# SWM181 register map
File version: 1.0
CPU: CM0 r1p0, little endian, 2 interrupt priority bits
Registers are 32-bit, read-write, no defined reset value unless marked. A register's access mark holds for its fields unless they carry their own. Offsets are from the block's base; [hi:lo] are bit positions; lines under a group give offsets from that group; {n}, {i} and the like mark numbered series; 'fields as' and 'values as' point back to an identical list.

## ADC — Registers group
Base 0x5000D000
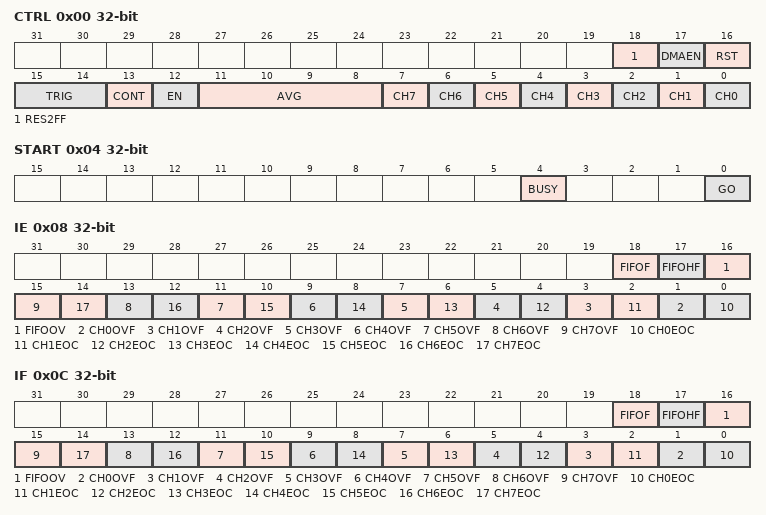
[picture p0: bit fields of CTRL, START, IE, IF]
0x00 CTRL
  [18] RES2FF, [17] DMAEN, [16] RST, [15:14] TRIG, [13] CONT, [12] EN, [11:8] AVG, [n] CH{n} (n=0..7)
0x04 START
  [4] BUSY, [0] GO
0x08 IE
  [18] FIFOF, [17] FIFOHF, [16] FIFOOV, [2n+1] CH{n}OVF (n=0..7), [2n] CH{n}EOC (n=0..7)
0x0C IF
  fields as IE
{0x10+0x10*i} CH{i} group (i=0..7) — register cluster
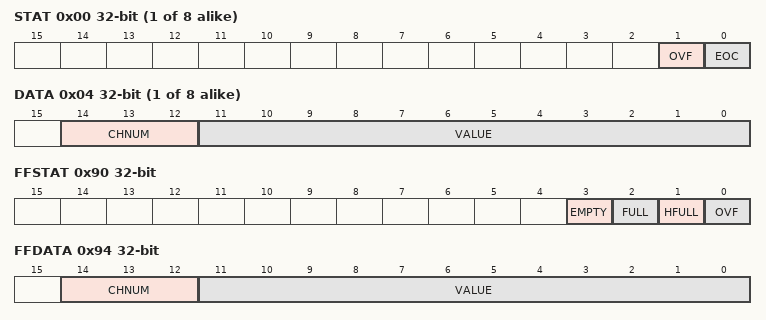
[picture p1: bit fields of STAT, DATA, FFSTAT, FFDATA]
  0x00 STAT
    [1] OVF, [0] EOC
  0x04 DATA
    [14:12] CHNUM, [11:0] VALUE
0x90 FFSTAT
  [3] EMPTY, [2] FULL, [1] HFULL, [0] OVF
0x94 FFDATA
  [14:12] CHNUM, [11:0] VALUE

## SDADC — Registers group
Base 0x50040000
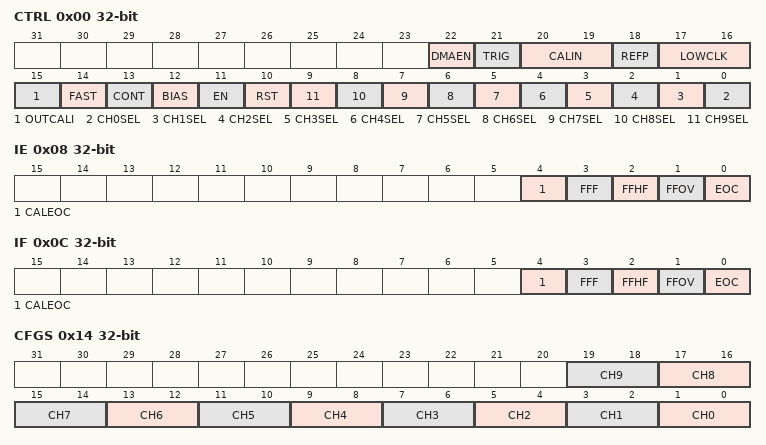
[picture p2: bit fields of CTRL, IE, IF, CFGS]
0x00 CTRL
  [22] DMAEN, [21] TRIG, [20:19] CALIN, [18] REFP, [17:16] LOWCLK, [15] OUTCALI, [14] FAST, [13] CONT, [12] BIAS, [11] EN, [10] RST, [n] CH{n}SEL (n=0..9)
0x04 START
  [0] GO
0x08 IE
  [4] CALEOC, [3] FFF, [2] FFHF, [1] FFOV, [0] EOC
0x0C IF
  [4] CALEOC, [3] FFF, [2] FFHF, [1] FFOV, [0] EOC
0x14 CFGS
  [2n+1:2n] CH{n} (n=0..9)
0x20 CFGA
0x24 CFGB
0x28 CFGC
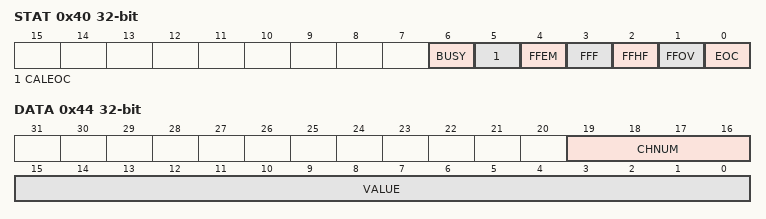
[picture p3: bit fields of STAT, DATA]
0x40 STAT
  [6] BUSY, [5] CALEOC, [4] FFEM, [3] FFF, [2] FFHF, [1] FFOV, [0] EOC
0x44 DATA
  [19:16] CHNUM, [15:0] VALUE

## PWM0 — Registers group
Base 0x5000A000
Same registers: PWM1 0x5000A020, PWM2 0x5000A040, PWM3 0x5000A060
0x00 MODE
0x04 PERA
0x08 HIGHA
0x0C DZA
0x10 PERB
0x14 HIGHB
0x18 DZB
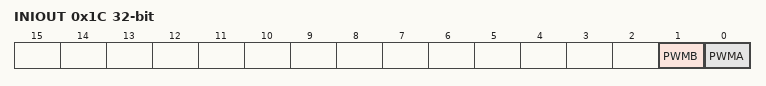
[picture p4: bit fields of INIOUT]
0x1C INIOUT
  [1] PWMB, [0] PWMA

## PWMG — Registers group
Base 0x5000A170
0x00 CLKDIV
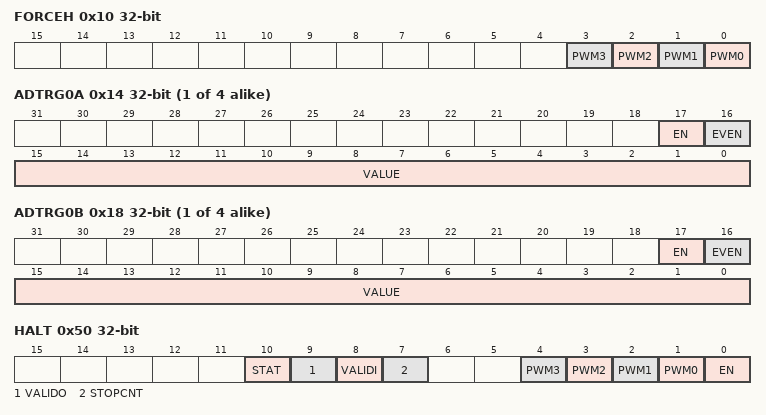
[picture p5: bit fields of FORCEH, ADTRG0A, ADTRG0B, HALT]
0x10 FORCEH
  [n] PWM{n} (n=0..3)
{0x14+8i} ADTRG{i}A (i=0..3)
  [17] EN, [16] EVEN, [15:0] VALUE
{0x18+8i} ADTRG{i}B (i=0..3)
  [17] EN, [16] EVEN, [15:0] VALUE
0x50 HALT
  [10] STAT, [9] VALIDO, [8] VALIDI, [7] STOPCNT, [n+1] PWM{n} (n=0..3), [0] EN
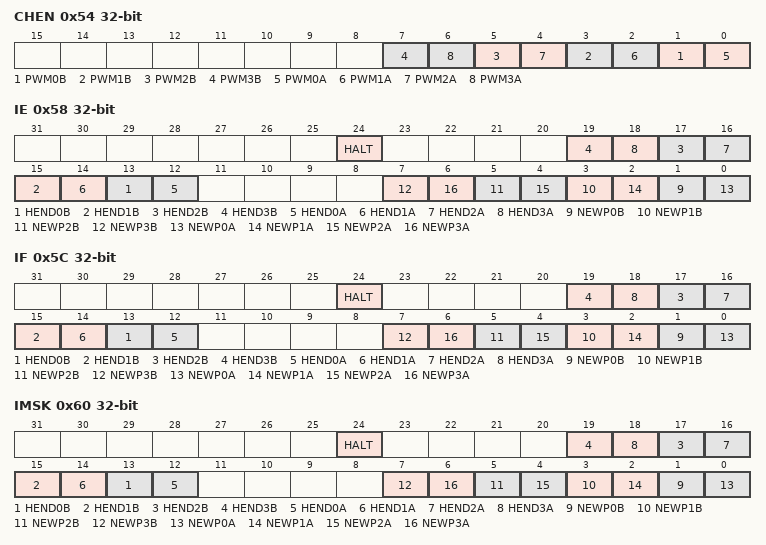
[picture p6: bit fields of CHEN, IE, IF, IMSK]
0x54 CHEN
  [2n+1] PWM{n}B (n=0..3), [2n] PWM{n}A (n=0..3)
0x58 IE
  [24] HALT, [2n+13] HEND{n}B (n=0..3), [2n+12] HEND{n}A (n=0..3), [2n+1] NEWP{n}B (n=0..3), [2n] NEWP{n}A (n=0..3)
0x5C IF
  fields as IE
0x60 IMSK
  fields as IE
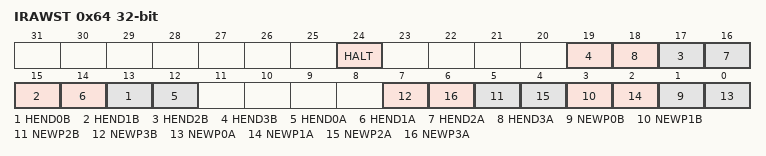
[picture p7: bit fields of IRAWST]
0x64 IRAWST
  fields as IE

## DMA — Registers group
Base 0x41000000
0x00 EN
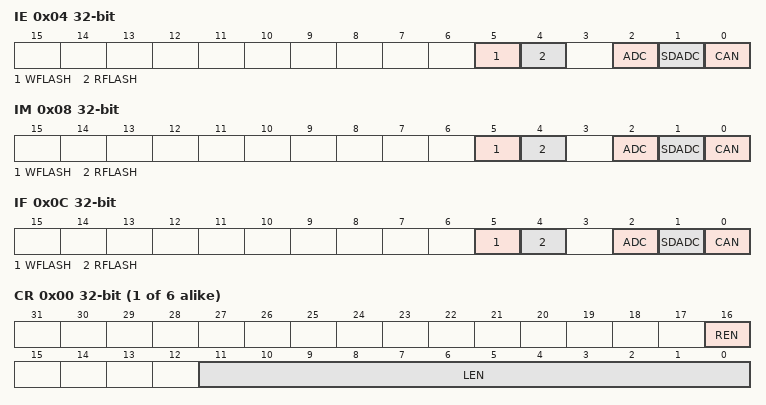
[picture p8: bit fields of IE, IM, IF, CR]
0x04 IE
  [5] WFLASH, [4] RFLASH, [2] ADC, [1] SDADC, [0] CAN
0x08 IM
  [5] WFLASH, [4] RFLASH, [2] ADC, [1] SDADC, [0] CAN
0x0C IF
  [5] WFLASH, [4] RFLASH, [2] ADC, [1] SDADC, [0] CAN
{0x10+0xC*i} CH{i} group (i=0..5) — register cluster
  0x00 CR
    [16] REN, [11:0] LEN
  0x04 SRC
  0x08 DST

## CAN — Registers group
Base 0x50020000
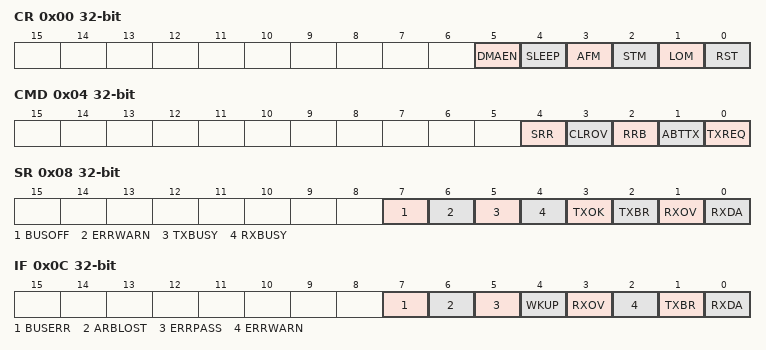
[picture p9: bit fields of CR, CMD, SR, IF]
0x00 CR
  [5] DMAEN, [4] SLEEP, [3] AFM, [2] STM, [1] LOM, [0] RST
0x04 CMD wo
  [4] SRR, [3] CLROV, [2] RRB, [1] ABTTX, [0] TXREQ
0x08 SR ro
  [7] BUSOFF, [6] ERRWARN, [5] TXBUSY, [4] RXBUSY, [3] TXOK, [2] TXBR, [1] RXOV, [0] RXDA
0x0C IF ro
  [7] BUSERR, [6] ARBLOST, [5] ERRPASS, [4] WKUP, [3] RXOV, [2] ERRWARN, [1] TXBR, [0] RXDA
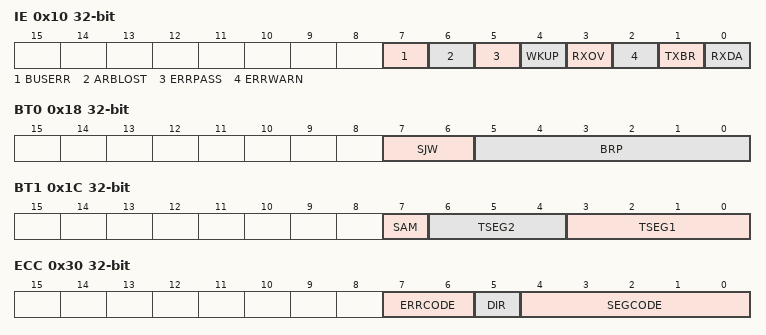
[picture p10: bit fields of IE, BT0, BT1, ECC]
0x10 IE
  fields as IF
0x18 BT0
  [7:6] SJW, [5:0] BRP
0x1C BT1
  [7] SAM, [6:4] TSEG2, [3:0] TSEG1
0x2C ALC ro
0x30 ECC ro
  [7:6] ERRCODE, [5] DIR, [4:0] SEGCODE
0x34 EWLIM
0x38 RXERR
0x3C TXERR
0x40 FILTER group — register cluster
  {0x0+4j} ACR[{j}] (j=0..3)
  {0x10+4j} AMR[{j}] (j=0..3)
0x40 FRAME group (alternate view of FILTER) — register cluster
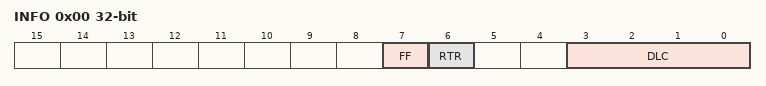
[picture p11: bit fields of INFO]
  0x00 INFO
    [7] FF, [6] RTR, [3:0] DLC
  {0x4+4j} DATA[{j}] (j=0..11)
0x74 RMCNT ro
0x180 TXFRAME_R group — register cluster
  0x00 INFO ro
    [7] FF, [6] RTR, [3:0] DLC
  {0x4+4j} DATA[{j}] (j=0..11) ro

## SLCD — Registers group
Base 0x50050000
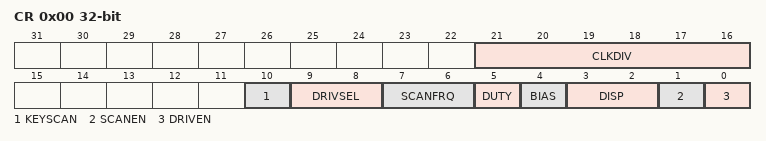
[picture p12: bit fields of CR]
0x00 CR
  [21:16] CLKDIV, [10] KEYSCAN, [9:8] DRIVSEL, [7:6] SCANFRQ, [5] DUTY, [4] BIAS, [3:2] DISP, [1] SCANEN, [0] DRIVEN
{0x10+4i} DATA[{i}] (i=0..3)

## WDT — Registers group
Base 0x50009000
0x00 LOAD
0x04 VALUE ro
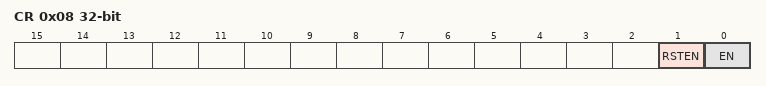
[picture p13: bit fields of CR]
0x08 CR
  [1] RSTEN, [0] EN
0x0C IF
0x10 FEED

## DIV — Registers group
Base 0x46000000
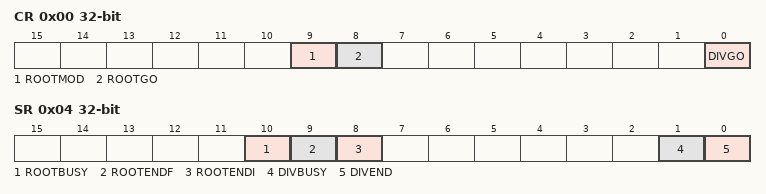
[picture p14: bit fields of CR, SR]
0x00 CR
  [9] ROOTMOD, [8] ROOTGO, [0] DIVGO
0x04 SR
  [10] ROOTBUSY, [9] ROOTENDF, [8] ROOTENDI, [1] DIVBUSY, [0] DIVEND
0x10 DIVIDEND
0x14 DIVISOR
0x18 QUO
0x1C REMAIN
0x20 RADICAND
0x24 ROOT

## CORDIC — Registers group
Base 0x47000000
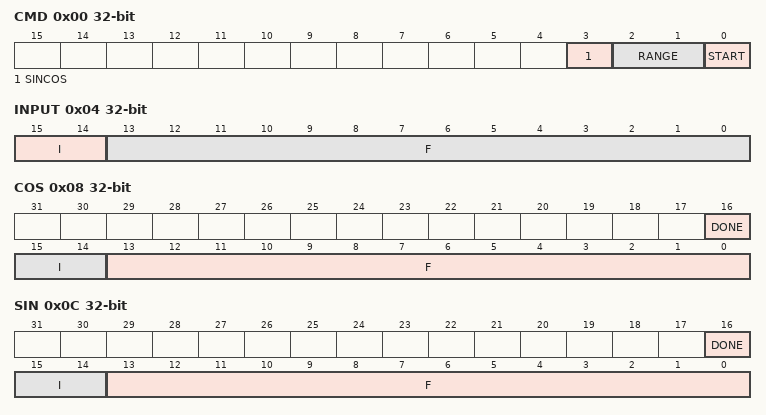
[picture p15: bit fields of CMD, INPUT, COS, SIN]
0x00 CMD
  [3] SINCOS, [2:1] RANGE, [0] START
0x04 INPUT
  [15:14] I, [13:0] F
0x08 COS
  [16] DONE, [15:14] I, [13:0] F
0x0C SIN
  [16] DONE, [15:14] I, [13:0] F
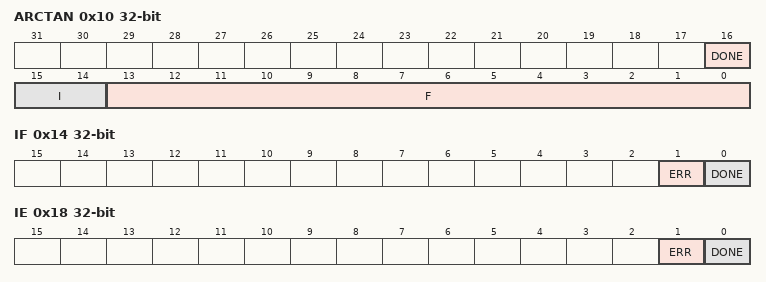
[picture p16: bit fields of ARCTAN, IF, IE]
0x10 ARCTAN
  [16] DONE, [15:14] I, [13:0] F
0x14 IF
  [1] ERR, [0] DONE
0x18 IE
  [1] ERR, [0] DONE
